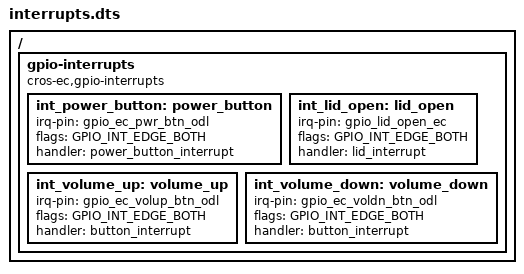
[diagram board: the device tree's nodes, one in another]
/* Copyright 2022 The Chromium OS Authors. All rights reserved.
 * Use of this source code is governed by a BSD-style license that can be
 * found in the LICENSE file.
 */

/ {
	gpio-interrupts {
		compatible = "cros-ec,gpio-interrupts";

		int_power_button: power_button {
			irq-pin = <&gpio_ec_pwr_btn_odl>;
			flags = <GPIO_INT_EDGE_BOTH>;
			handler = "power_button_interrupt";
		};
		int_lid_open: lid_open {
			irq-pin = <&gpio_lid_open_ec>;
			flags = <GPIO_INT_EDGE_BOTH>;
			handler = "lid_interrupt";
		};
		int_volume_up: volume_up {
			irq-pin = <&gpio_ec_volup_btn_odl>;
			flags = <GPIO_INT_EDGE_BOTH>;
			handler = "button_interrupt";
		};
		int_volume_down: volume_down {
			irq-pin = <&gpio_ec_voldn_btn_odl>;
			flags = <GPIO_INT_EDGE_BOTH>;
			handler = "button_interrupt";
		};
	};
};
